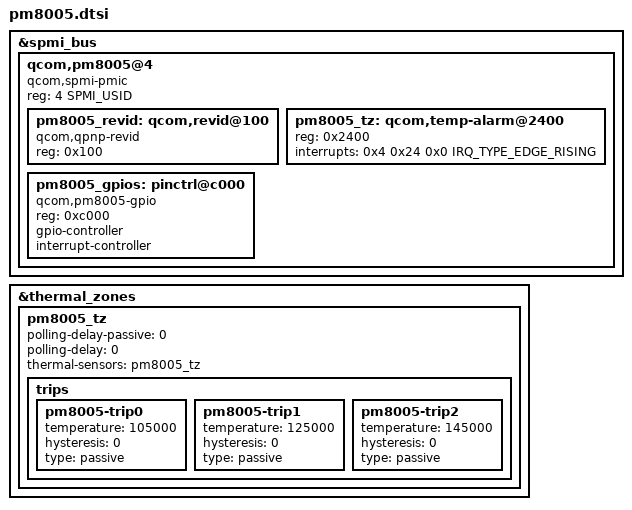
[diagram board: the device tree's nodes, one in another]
#include <dt-bindings/spmi/spmi.h>
#include <dt-bindings/interrupt-controller/irq.h>

&spmi_bus {
	qcom,pm8005@4 {
		compatible = "qcom,spmi-pmic";
		reg = <4 SPMI_USID>;
		#address-cells = <1>;
		#size-cells = <0>;

		pm8005_revid: qcom,revid@100 {
			compatible = "qcom,qpnp-revid";
			reg = <0x100>;
		};

		pm8005_tz: qcom,temp-alarm@2400 {
			reg = <0x2400>;
			interrupts = <0x4 0x24 0x0 IRQ_TYPE_EDGE_RISING>;
			#thermal-sensor-cells = <0>;
		};

		pm8005_gpios: pinctrl@c000 {
			compatible = "qcom,pm8005-gpio";
			reg = <0xc000>;
			gpio-controller;
			#gpio-cells = <2>;
			interrupt-controller;
			#interrupt-cells = <2>;
		};
	};
};

&thermal_zones {
	pm8005_tz {
		polling-delay-passive = <0>;
		polling-delay = <0>;
		thermal-sensors = <&pm8005_tz>;

		trips {
			pm8005-trip0 {
				temperature = <105000>;
				hysteresis = <0>;
				type = "passive";
			};

			pm8005-trip1 {
				temperature = <125000>;
				hysteresis = <0>;
				type = "passive";
			};

			pm8005-trip2 {
				temperature = <145000>;
				hysteresis = <0>;
				type = "passive";
			};
		};
	};
};
